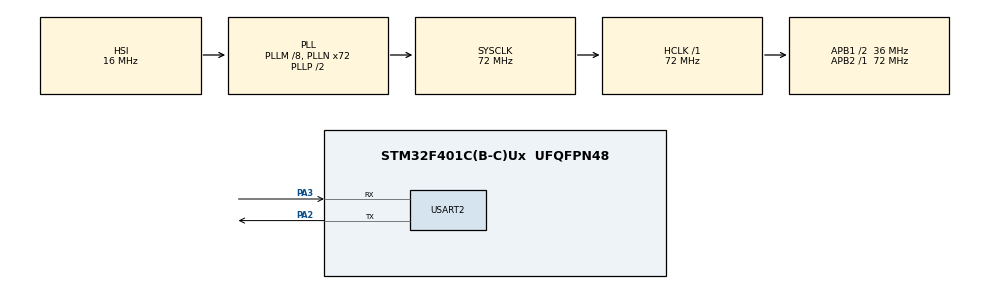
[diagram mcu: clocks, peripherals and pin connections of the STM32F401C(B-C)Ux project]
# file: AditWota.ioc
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Mcu.Family=STM32F4
Mcu.Name=STM32F401C(B-C)Ux
Mcu.Package=UFQFPN48
NVIC.PriorityGroup=NVIC_PRIORITYGROUP_4
NVIC.USART2_IRQn=true\:0\:0\:false\:false\:true\:true\:true\:true
PA13.Mode=Serial_Wire
PA13.Signal=SYS_JTMS-SWDIO
PA14.Mode=Serial_Wire
PA14.Signal=SYS_JTCK-SWCLK
PA2.Mode=Asynchronous
PA2.Signal=USART2_TX
PA3.Mode=Asynchronous
PA3.Signal=USART2_RX
PH0\ -\ OSC_IN.Mode=HSE-External-Oscillator
PH0\ -\ OSC_IN.Signal=RCC_OSC_IN
PH1\ -\ OSC_OUT.Mode=HSE-External-Oscillator
PH1\ -\ OSC_OUT.Signal=RCC_OSC_OUT
ProjectManager.HeapSize=0x200
ProjectManager.StackSize=0x400
ProjectManager.TargetToolchain=STM32CubeIDE
RCC.48MHZClocksFreq_Value=36000000
RCC.AHBFreq_Value=72000000
RCC.APB1CLKDivider=RCC_HCLK_DIV2
RCC.APB1Freq_Value=36000000
RCC.APB1TimFreq_Value=72000000
RCC.APB2Freq_Value=72000000
RCC.APB2TimFreq_Value=72000000
RCC.CortexFreq_Value=72000000
RCC.HCLKFreq_Value=72000000
RCC.HSE_VALUE=25000000
RCC.HSI_VALUE=16000000
RCC.LSE_VALUE=32768
RCC.PLLM=8
RCC.PLLN=72
RCC.SYSCLKFreq_VALUE=72000000
RCC.SYSCLKSource=RCC_SYSCLKSOURCE_PLLCLK
RCC.VCOOutputFreq_Value=144000000
USART2.VirtualMode=VM_ASYNC
board=custom

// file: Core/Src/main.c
/* USER CODE BEGIN Header */
/**
  ******************************************************************************
  * @file           : main.c
  * @brief          : Main program body
  ******************************************************************************
  * @attention
  *
  * Copyright (c) 2024 STMicroelectronics.
  * All rights reserved.
  *
  * This software is licensed under terms that can be found in the LICENSE file
  * in the root directory of this software component.
  * If no LICENSE file comes with this software, it is provided AS-IS.
  *
  ******************************************************************************
  */
/* USER CODE END Header */
#include "main.h"
#include <stdio.h>

UART_HandleTypeDef huart2;

/* USER CODE BEGIN PV */
float tps = 3;
int rpm = 0.00;
int temperature = 10;
char tpsBuff[7];
char tempBuff[4];
char rpmBuff[5];
//char espData[12];

/* USER CODE END PV */

void SystemClock_Config(void);
static void MX_GPIO_Init(void);
static void MX_USART2_UART_Init(void);
//void sendUsartArray();
void processData(uint8_t *data);

/* USER CODE BEGIN 0 */
void processData(uint8_t *data) {
	rpm = (uint16_t) (data[4]<<8) + data[5];
	snprintf(rpmBuff, sizeof(rpmBuff), "%02X", rpm);

	  HAL_UART_Transmit_IT(&huart2, rpmBuff, sizeof(rpmBuff));

//	tps = (float) (data[7]*100)/255;
//	temperature = (int) data[9] - 40;
//	//uint8_t rpmBuff, uint8_t tpsBuff, uint8_t temperatureBuff
//	 sprintf(dataSend, "%02i %02x %02i", rpm, tps, temperature);
//	 HAL_UART_Transmit_IT(&huart2, dataSend, sizeof(dataSend));
}

//void sendUsartArray()
//{
//	rpm = (uint16_t) (data[4]<<8) + data[5];
//
//	 uint8_t dataSend[12];
//	    snprintf(rpmBuff, sizeof(rpmBuff), "%02X", rpm);
//	    snprintf(tpsBuff, sizeof(tpsBuff), "%02X", (int)tps);
//	    snprintf(tempBuff, sizeof(tempBuff), "%02X", temperature);

//	    sprintf(dataSend, "%s", rpmBuff);
//
//	    HAL_UART_Transmit_IT(&huart2, dataSend, sizeof(dataSend));

//  uint8_t dataSend[4] = {rpm,tps,temperature};
//  char dataSendArray[12];
//  snprintf(dataSendArray, sizeof(dataSendArray), "%02x %02x %02x", dataSend[0], dataSend[1], dataSend[2]);
//  HAL_UART_Transmit_IT(&huart2, dataSend, Sizeof(dataSend),10);_
////  Serial2.write((uint8_t *)&dataSendArray, sizeof(dataSendArray));
//}

/* USER CODE END 0 */

int main(void)
{

  /* MCU Configuration--------------------------------------------------------*/

  /* Reset of all peripherals, Initializes the Flash interface and the Systick. */
  HAL_Init();

  /* Configure the system clock */
  SystemClock_Config();

  /* Initialize all configured peripherals */
  MX_GPIO_Init();
  MX_USART2_UART_Init();

  /* Infinite loop */
  while (1)
  {
	  uint8_t putaran = 177;
	  processData(putaran);
  }
}

void SystemClock_Config(void)
{
  RCC_OscInitTypeDef RCC_OscInitStruct = {0};
  RCC_ClkInitTypeDef RCC_ClkInitStruct = {0};

  /** Configure the main internal regulator output voltage
  */
  __HAL_RCC_PWR_CLK_ENABLE();
  __HAL_PWR_VOLTAGESCALING_CONFIG(PWR_REGULATOR_VOLTAGE_SCALE2);

  /** Initializes the RCC Oscillators according to the specified parameters
  * in the RCC_OscInitTypeDef structure.
  */
  RCC_OscInitStruct.OscillatorType = RCC_OSCILLATORTYPE_HSI;
  RCC_OscInitStruct.HSIState = RCC_HSI_ON;
  RCC_OscInitStruct.HSICalibrationValue = RCC_HSICALIBRATION_DEFAULT;
  RCC_OscInitStruct.PLL.PLLState = RCC_PLL_ON;
  RCC_OscInitStruct.PLL.PLLSource = RCC_PLLSOURCE_HSI;
  RCC_OscInitStruct.PLL.PLLM = 8;
  RCC_OscInitStruct.PLL.PLLN = 72;
  RCC_OscInitStruct.PLL.PLLP = RCC_PLLP_DIV2;
  RCC_OscInitStruct.PLL.PLLQ = 4;
  if (HAL_RCC_OscConfig(&RCC_OscInitStruct) != HAL_OK)
  {
    Error_Handler();
  }

  /** Initializes the CPU, AHB and APB buses clocks
  */
  RCC_ClkInitStruct.ClockType = RCC_CLOCKTYPE_HCLK|RCC_CLOCKTYPE_SYSCLK
                              |RCC_CLOCKTYPE_PCLK1|RCC_CLOCKTYPE_PCLK2;
  RCC_ClkInitStruct.SYSCLKSource = RCC_SYSCLKSOURCE_PLLCLK;
  RCC_ClkInitStruct.AHBCLKDivider = RCC_SYSCLK_DIV1;
  RCC_ClkInitStruct.APB1CLKDivider = RCC_HCLK_DIV2;
  RCC_ClkInitStruct.APB2CLKDivider = RCC_HCLK_DIV1;

  if (HAL_RCC_ClockConfig(&RCC_ClkInitStruct, FLASH_LATENCY_2) != HAL_OK)
  {
    Error_Handler();
  }
}

static void MX_USART2_UART_Init(void)
{

  huart2.Instance = USART2;
  huart2.Init.BaudRate = 115200;
  huart2.Init.WordLength = UART_WORDLENGTH_8B;
  huart2.Init.StopBits = UART_STOPBITS_1;
  huart2.Init.Parity = UART_PARITY_NONE;
  huart2.Init.Mode = UART_MODE_TX_RX;
  huart2.Init.HwFlowCtl = UART_HWCONTROL_NONE;
  huart2.Init.OverSampling = UART_OVERSAMPLING_16;
  if (HAL_UART_Init(&huart2) != HAL_OK)
  {
    Error_Handler();
  }

}

static void MX_GPIO_Init(void)
{

  /* GPIO Ports Clock Enable */
  __HAL_RCC_GPIOH_CLK_ENABLE();
  __HAL_RCC_GPIOA_CLK_ENABLE();

}

void Error_Handler(void)
{
  __disable_irq();
  while (1)
  {
  }
}
